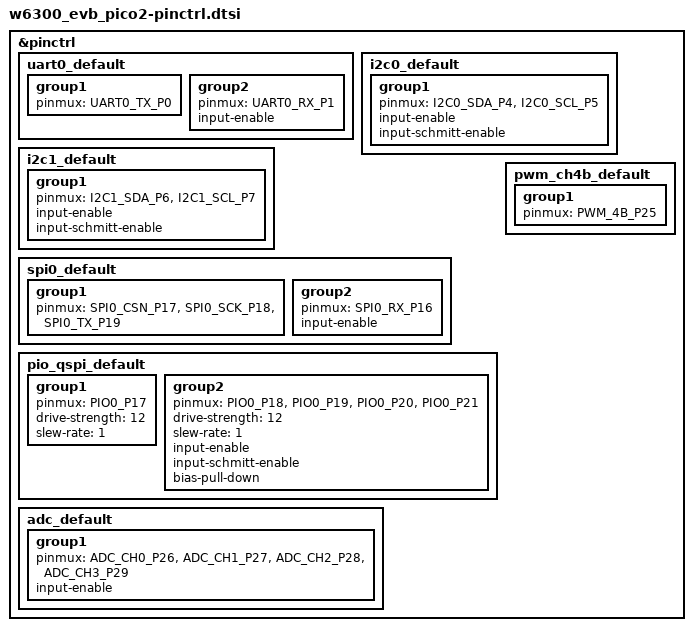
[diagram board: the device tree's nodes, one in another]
/*
 * Copyright (c) 2026 WIZnet Co., Ltd.
 * SPDX-License-Identifier: Apache-2.0
 */

#include <zephyr/dt-bindings/pinctrl/rpi-pico-rp2350a-pinctrl.h>

&pinctrl {
	uart0_default: uart0_default {
		group1 {
			pinmux = <UART0_TX_P0>;
		};

		group2 {
			pinmux = <UART0_RX_P1>;
			input-enable;
		};
	};

	i2c0_default: i2c0_default {
		group1 {
			pinmux = <I2C0_SDA_P4>, <I2C0_SCL_P5>;
			input-enable;
			input-schmitt-enable;
		};
	};

	i2c1_default: i2c1_default {
		group1 {
			pinmux = <I2C1_SDA_P6>, <I2C1_SCL_P7>;
			input-enable;
			input-schmitt-enable;
		};
	};

	spi0_default: spi0_default {
		group1 {
			pinmux = <SPI0_CSN_P17>, <SPI0_SCK_P18>, <SPI0_TX_P19>;
		};

		group2 {
			pinmux = <SPI0_RX_P16>;
			input-enable;
		};
	};

	pio_qspi_default: pio_qspi_default {
		/* SCK (GPIO17) - high drive strength, fast slew rate */
		group1 {
			pinmux = <PIO0_P17>;
			drive-strength = <12>;
			slew-rate = <1>;
		};

		/* IO0-IO3 (GPIO18-21) - bidirectional, schmitt trigger, pull-down */
		group2 {
			pinmux = <PIO0_P18>, <PIO0_P19>, <PIO0_P20>, <PIO0_P21>;
			drive-strength = <12>;
			slew-rate = <1>;
			input-enable;
			input-schmitt-enable;
			bias-pull-down;
		};
	};

	pwm_ch4b_default: pwm_ch4b_default {
		group1 {
			pinmux = <PWM_4B_P25>;
		};
	};

	adc_default: adc_default {
		group1 {
			pinmux = <ADC_CH0_P26>, <ADC_CH1_P27>, <ADC_CH2_P28>, <ADC_CH3_P29>;
			input-enable;
		};
	};
};
